# nrf7140_wificore register map
Vendor: Nordic Semiconductor; Series: nRF71; File version: 1
Registers are 32-bit, read-write, reset 0x0 unless marked. A register's access mark holds for its fields unless they carry their own. Offsets are from the block's base; [hi:lo] are bit positions; lines under a group give offsets from that group; {n}, {i} and the like mark numbered series; 'fields as' and 'values as' point back to an identical list.

## GLOBAL_RAMC122 — RAM Controller 0
Base 0x5F8DA000
Same registers: GLOBAL_RAMC123 0x5F8DD000
0x500 WAITSTATES — Waitstates for read operations.
  [0] WAITSTATES — Number of waitstates for a read from the RAM.

## GLOBAL_DPPIC120 — Distributed programmable peripheral interconnect controller 0
Base 0x5F8E1000
Same registers: GLOBAL_DPPIC130 0x5F922000, GLOBAL_DPPIC131 0x5F981000, GLOBAL_DPPIC132 0x5F991000, GLOBAL_DPPIC133 0x5F9A1000, GLOBAL_DPPIC134 0x5F9B1000, GLOBAL_DPPIC135 0x5F9C1000, GLOBAL_DPPIC136 0x5F9D1000
{0x0+8i} TASKS_CHG[{i}] (i=0..3) group — Channel group tasks
  0x00 EN wo — Description cluster: Enable channel group n
    [0] EN — Enable channel group n
      1=Trigger task
  0x04 DIS wo — Description cluster: Disable channel group n
    [0] DIS — Disable channel group n
      1=Trigger task
{0x80+8i} SUBSCRIBE_CHG[{i}] (i=0..3) group — Subscribe configuration for tasks
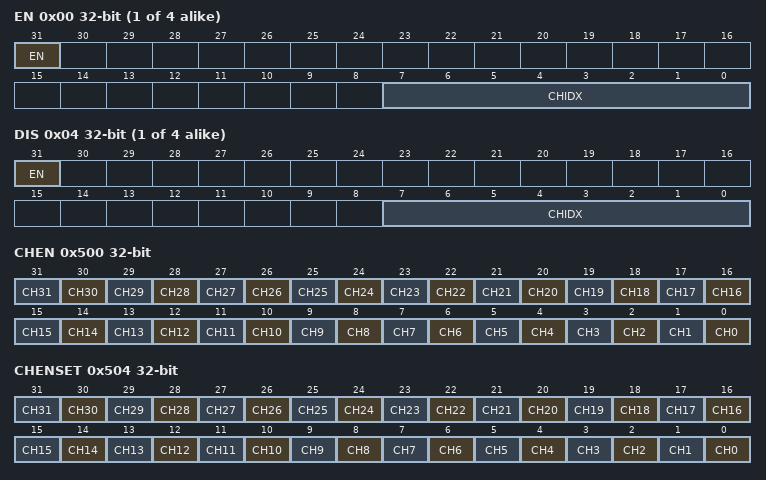
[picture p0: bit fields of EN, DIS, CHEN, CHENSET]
  0x00 EN — Description cluster: Subscribe configuration for task CHG[n].EN
    [31] EN
      0=Disabled (Disable subscription); 1=Enabled (Enable subscription)
    [7:0] CHIDX — DPPI channel that task CHG[n].EN will subscribe to
  0x04 DIS — Description cluster: Subscribe configuration for task CHG[n].DIS
    [31] EN
      values as SUBSCRIBE_CHG[0].EN.EN
    [7:0] CHIDX — DPPI channel that task CHG[n].DIS will subscribe to
0x500 CHEN — Channel enable register
  [all] fields
    0=Disabled (Disable channel); 1=Enabled (Enable channel)
  [n] CH{n} (n=0..31) — Enable or disable channel {n}
0x504 CHENSET write-1-sets — Channel enable set register
  [all] fields
    on read: 0=Disabled (Read: Channel disabled); 1=Enabled (Read: Channel enabled) | on write: 1=Set (Write: Enable channel)
  [n] CH{n} (n=0..31) — Channel {n} enable set register. Writing 0 has no effect.
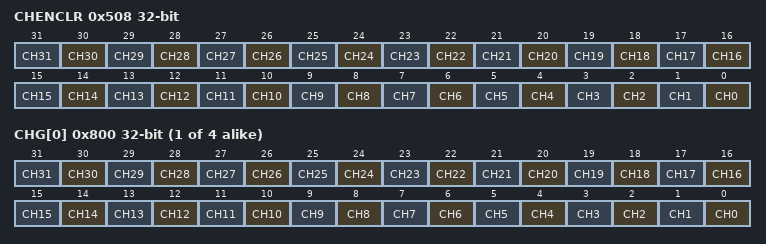
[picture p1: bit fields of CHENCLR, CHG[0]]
0x508 CHENCLR write-1-clears — Channel enable clear register
  [all] fields
    on read: 0=Disabled (Read: Channel disabled); 1=Enabled (Read: Channel enabled) | on write: 1=Clear (Write: Disable channel)
  [n] CH{n} (n=0..31) — Channel {n} enable clear register. Writing 0 has no effect.
{0x800+4i} CHG[{i}] (i=0..3) — Description collection: Channel group n Note: Writes to this register are ignored if either SUBSCRIBE_CHG[n].EN or SUBSCRIBE_CHG[n].DIS is enabled
  [all] fields
    0=Excluded; 1=Included
  [n] CH{n} (n=0..31) — Include or exclude channel {n}

## GLOBAL_EGU130 — Event generator unit
Base 0x5F92D000
{0x0+4i} TASKS_TRIGGER[{i}] (i=0..15) wo — Description collection: Trigger n for triggering the corresponding TRIGGERED[n] event
  [0] TASKS_TRIGGER — Trigger n for triggering the corresponding TRIGGERED[n] event
    1=Trigger task
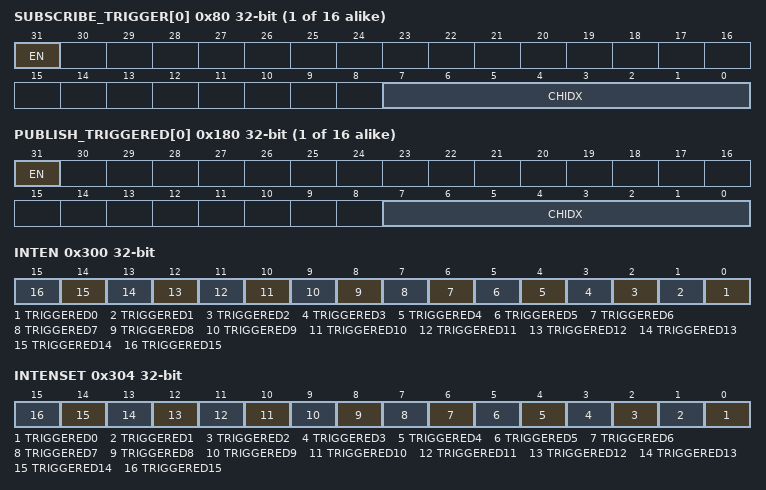
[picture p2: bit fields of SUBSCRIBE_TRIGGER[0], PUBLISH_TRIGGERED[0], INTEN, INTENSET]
{0x80+4i} SUBSCRIBE_TRIGGER[{i}] (i=0..15) — Description collection: Subscribe configuration for task TRIGGER[n]
  [31] EN
    0=Disabled (Disable subscription); 1=Enabled (Enable subscription)
  [7:0] CHIDX — DPPI channel that task TRIGGER[n] will subscribe to
{0x100+4i} EVENTS_TRIGGERED[{i}] (i=0..15) — Description collection: Event number n generated by triggering the corresponding TRIGGER[n] task
  [0] EVENTS_TRIGGERED — Event number n generated by triggering the corresponding TRIGGER[n] task
    0=NotGenerated (Event not generated); 1=Generated (Event generated)
{0x180+4i} PUBLISH_TRIGGERED[{i}] (i=0..15) — Description collection: Publish configuration for event TRIGGERED[n]
  [31] EN
    0=Disabled (Disable publishing); 1=Enabled (Enable publishing)
  [7:0] CHIDX — DPPI channel that event TRIGGERED[n] will publish to
0x300 INTEN — Enable or disable interrupt
  [all] fields
    0=Disabled; 1=Enabled
  [n] TRIGGERED{n} (n=0..15) — Enable or disable interrupt for event TRIGGERED[{n}]
0x304 INTENSET — Enable interrupt
  [all] fields
    on read: 0=Disabled (Read: Disabled); 1=Enabled (Read: Enabled) | on write: 1=Set (Enable)
  [n] TRIGGERED{n} (n=0..15) — Write '1' to enable interrupt for event TRIGGERED[{n}]
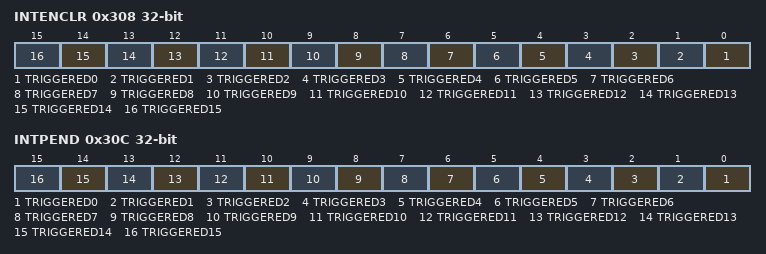
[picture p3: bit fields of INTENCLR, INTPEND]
0x308 INTENCLR — Disable interrupt
  [all] fields
    on read: 0=Disabled (Read: Disabled); 1=Enabled (Read: Enabled) | on write: 1=Clear (Disable)
  [n] TRIGGERED{n} (n=0..15) — Write '1' to disable interrupt for event TRIGGERED[{n}]
0x30C INTPEND ro — Pending interrupts
  [all] fields
    on read: 0=NotPending (Read: Not pending); 1=Pending (Read: Pending)
  [n] TRIGGERED{n} (n=0..15) — Read pending status of interrupt for event TRIGGERED[{n}]
